# LPC408x_7x register map
File version: 0.7
CPU: CM4 r0p0, little endian, no MPU, no FPU, 3 interrupt priority bits
Registers are 32-bit, read-write, reset 0x0 unless marked. A register's access mark holds for its fields unless they carry their own. Offsets are from the block's base; [hi:lo] are bit positions; {n}, {i} and the like mark numbered series; 'fields as' and 'values as' point back to an identical list.

## UART0 — UART0/2/3
Base 0x4000C000
Same registers: UART2 0x40098000, UART3 0x4009C000
0x00 RBR ro reset not defined read-modifies — Receiver Buffer Register. Contains the next received character to be read (DLAB =0).
  [7:0] RBR — The UARTn Receiver Buffer Register contains the oldest received byte in the UARTn Rx FIFO.
0x00 THR wo reset not defined (alternate view of RBR) — Transmit Holding Regiter. The next character to be transmitted is written here (DLAB =0).
  [7:0] THR — Writing to the UARTn Transmit Holding Register causes the data to be stored in the UARTn transmit FIFO. The byte will be sent when it reaches the bottom of the FIFO and the transmitter is available.
0x00 DLL reset 0x1 (alternate view of RBR) — Divisor Latch LSB. Least significant byte of the baud rate divisor value. The full divisor is used to generate a baud rate from the fractional rate divider (DLAB =1).
  [7:0] DLLSB — The UARTn Divisor Latch LSB Register, along with the UnDLM register, determines the baud rate of the UARTn.
0x04 DLM — Divisor Latch MSB. Most significant byte of the baud rate divisor value. The full divisor is used to generate a baud rate from the fractional rate divider (DLAB =1).
  [7:0] DLMSB — The UARTn Divisor Latch MSB Register, along with the U0DLL register, determines the baud rate of the UARTn.
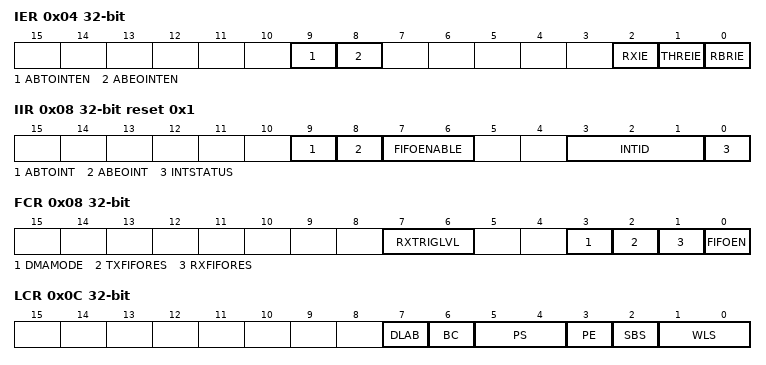
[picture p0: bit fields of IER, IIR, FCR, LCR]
0x04 IER (alternate view of DLM) — Interrupt Enable Register. Contains individual interrupt enable bits for the 7 potential UART interrupts (DLAB =0).
  [9] ABTOINTEN — Enables the auto-baud time-out interrupt.
    0=DISABLE_AUTO_BAUD_TI (Disable auto-baud time-out Interrupt.); 1=ENABLE_AUTO_BAUD_TIM (Enable auto-baud time-out Interrupt.)
  [8] ABEOINTEN — Enables the end of auto-baud interrupt.
    0=DISABLE_END_OF_AUTO_ (Disable end of auto-baud Interrupt.); 1=ENABLE_END_OF_AUTO_B (Enable end of auto-baud Interrupt.)
  [2] RXIE — RX Line Status Interrupt Enable. Enables the UARTn RX line status interrupts. The status of this interrupt can be read from UnLSR[4:1].
    0=DISABLE_THE_RX_LINE_ (Disable the RX line status interrupts.); 1=ENABLE_THE_RX_LINE_S (Enable the RX line status interrupts.)
  [1] THREIE — THRE Interrupt Enable. Enables the THRE interrupt for UARTn. The status of this can be read from UnLSR[5].
    0=DISABLE_THE_THRE_INT (Disable the THRE interrupts.); 1=ENABLE_THE_THRE_INTE (Enable the THRE interrupts.)
  [0] RBRIE — RBR Interrupt Enable. Enables the Receive Data Available interrupt for UARTn. It also controls the Character Receive Time-out interrupt.
    0=DISABLE_THE_RDA_INTE (Disable the RDA interrupts.); 1=ENABLE_THE_RDA_INTER (Enable the RDA interrupts.)
0x08 IIR ro reset 0x1 — Interrupt ID Register. Identifies which interrupt(s) are pending.
  [9] ABTOINT — Auto-baud time-out interrupt. True if auto-baud has timed out and interrupt is enabled.
  [8] ABEOINT — End of auto-baud interrupt. True if auto-baud has finished successfully and interrupt is enabled.
  [7:6] FIFOENABLE — Copies of UnFCR[0].
  [3:1] INTID — Interrupt identification. UnIER[3:1] identifies an interrupt corresponding to the UARTn Rx or TX FIFO. All other combinations of UnIER[3:1] not listed below are reserved (000,100,101,111).
    3=1_RECEIVE_LINE_S (1 - Receive Line Status (RLS).); 2=2A__RECEIVE_DATA_AV (2a - Receive Data Available (RDA).); 6=2B__CHARACTER_TIME_ (2b - Character Time-out Indicator (CTI).); 1=3_THRE_INTERRUPT
  [0] INTSTATUS — Interrupt status. Note that UnIIR[0] is active low. The pending interrupt can be determined by evaluating UnIIR[3:1].
    0=AT_LEAST_ONE_INTERRU (At least one interrupt is pending.); 1=NO_INTERRUPT_IS_PEND (No interrupt is pending.)
0x08 FCR wo (alternate view of IIR) — FIFO Control Register. Controls UART FIFO usage and modes.
  [7:6] RXTRIGLVL — RX Trigger Level. These two bits determine how many receiver UARTn FIFO characters must be written before an interrupt or DMA request is activated.
    0=TRIGGER_LEVEL_0_1_C (Trigger level 0 (1 character or 0x01).); 1=TRIGGER_LEVEL_1_4_C (Trigger level 1 (4 characters or 0x04).); 2=TRIGGER_LEVEL_2_8_C (Trigger level 2 (8 characters or 0x08).); 3=TRIGGER_LEVEL_3_14_ (Trigger level 3 (14 characters or 0x0E).)
  [3] DMAMODE — DMA Mode Select. When the FIFO enable (bit 0 of this register) is set, this bit selects the DMA mode. See Section 18.6.6.1.
  [2] TXFIFORES — TX FIFO Reset.
    0=NO_IMPACT_ON_EITHER_ (No impact on either of UARTn FIFOs.); 1=WRITING_A_LOGIC_1_TO (Writing a logic 1 to UnFCR[2] will clear all bytes in UARTn TX FIFO, reset the pointer logic. This bit is self-clearing.)
  [1] RXFIFORES — RX FIFO Reset.
    0=NO_IMPACT_ON_EITHER_ (No impact on either of UARTn FIFOs.); 1=WRITING_A_LOGIC_1_TO (Writing a logic 1 to UnFCR[1] will clear all bytes in UARTn Rx FIFO, reset the pointer logic. This bit is self-clearing.)
  [0] FIFOEN — FIFO Enable.
    0=UARTN_FIFOS_ARE_DISA (UARTn FIFOs are disabled. Must not be used in the application.); 1=ACTIVE_HIGH_ENABLE_F (Active high enable for both UARTn Rx and TX FIFOs and UnFCR[7:1] access. This bit must be set for proper UART operation. Any transition on this bit will automatically clear the related UART FIFOs.)
0x0C LCR — Line Control Register. Contains controls for frame formatting and break generation.
  [7] DLAB — Divisor Latch Access Bit
    0=DISABLE_ACCESS_TO_DI (Disable access to Divisor Latches.); 1=ENABLE_ACCESS_TO_DIV (Enable access to Divisor Latches.)
  [6] BC — Break Control
    0=DISABLE_BREAK_TRANSM (Disable break transmission.); 1=ENABLE_BREAK_TRANSMI (Enable break transmission. Output pin UARTn TXD is forced to logic 0 when UnLCR[6] is active high.)
  [5:4] PS — Parity Select
    0=ODD_PARITY_NUMBER_O (Odd parity. Number of 1s in the transmitted character and the attached parity bit will be odd.); 1=EVEN_PARITY_NUMBER_ (Even Parity. Number of 1s in the transmitted character and the attached parity bit will be even.); 2=FORCED_1_STICK_PARIT (Forced 1 stick parity.); 3=FORCED_0_STICK_PARIT (Forced 0 stick parity.)
  [3] PE — Parity Enable.
    0=DISABLE_PARITY_GENER (Disable parity generation and checking.); 1=ENABLE_PARITY_GENERA (Enable parity generation and checking.)
  [2] SBS — Stop Bit Select
    0=1_STOP_BIT_; 1=2_STOP_BITS_1_5_IF_ (2 stop bits (1.5 if UnLCR[1:0]=00).)
  [1:0] WLS — Word Length Select.
    {v}={v+5}_BIT_CHARACTER_LENG ({v+5}-bit character length) (v=0..3)
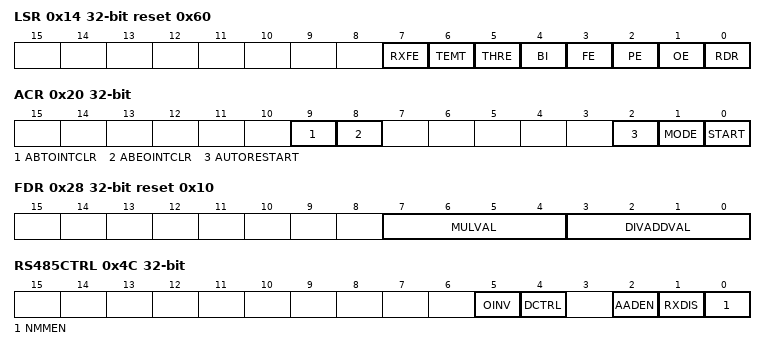
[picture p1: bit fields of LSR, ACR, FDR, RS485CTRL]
0x14 LSR ro reset 0x60 read-modifies — Line Status Register. Contains flags for transmit and receive status, including line errors.
  [7] RXFE — Error in RX FIFO . UnLSR[7] is set when a character with a Rx error such as framing error, parity error or break interrupt, is loaded into the UnRBR. This bit is cleared when the UnLSR register is read and there are no subsequent errors in the UARTn FIFO.
    0=NOERROR (UnRBR contains no UARTn RX errors or UnFCR[0]=0.); 1=ERRORS (UARTn RBR contains at least one UARTn RX error.)
  [6] TEMT — Transmitter Empty. TEMT is set when both UnTHR and UnTSR are empty; TEMT is cleared when either the UnTSR or the UnTHR contain valid data.
    0=VALIDDATA (UnTHR and/or the UnTSR contains valid data.); 1=EMPTY (UnTHR and the UnTSR are empty.)
  [5] THRE — Transmitter Holding Register Empty. THRE is set immediately upon detection of an empty UARTn THR and is cleared on a UnTHR write.
    0=VALIDDATA (UnTHR contains valid data.); 1=EMPTY (UnTHR is empty.)
  [4] BI — Break Interrupt. When RXDn is held in the spacing state (all zeroes) for one full character transmission (start, data, parity, stop), a break interrupt occurs. Once the break condition has been detected, the receiver goes idle until RXDn goes to marking state (all ones). An UnLSR read clears this status bit. The time of break detection is dependent on UnFCR[0]. Note: The break interrupt is associated with the character at the top of the UARTn RBR FIFO.
    0=INACTIVE (Break interrupt status is inactive.); 1=ACTIVE (Break interrupt status is active.)
  [3] FE — Framing Error. When the stop bit of a received character is a logic 0, a framing error occurs. An UnLSR read clears UnLSR[3]. The time of the framing error detection is dependent on UnFCR[0]. Upon detection of a framing error, the Rx will attempt to resynchronize to the data and assume that the bad stop bit is actually an early start bit. However, it cannot be assumed that the next received byte will be correct even if there is no Framing Error. Note: A framing error is associated with the character at the top of the UARTn RBR FIFO.
    0=INACTIVE (Framing error status is inactive.); 1=ACTIVE (Framing error status is active.)
  [2] PE — Parity Error. When the parity bit of a received character is in the wrong state, a parity error occurs. An UnLSR read clears UnLSR[2]. Time of parity error detection is dependent on UnFCR[0]. Note: A parity error is associated with the character at the top of the UARTn RBR FIFO.
    0=INACTIVE (Parity error status is inactive.); 1=ACTIVE (Parity error status is active.)
  [1] OE — Overrun Error. The overrun error condition is set as soon as it occurs. An UnLSR read clears UnLSR[1]. UnLSR[1] is set when UARTn RSR has a new character assembled and the UARTn RBR FIFO is full. In this case, the UARTn RBR FIFO will not be overwritten and the character in the UARTn RSR will be lost.
    0=INACTIVE (Overrun error status is inactive.); 1=ACTIVE (Overrun error status is active.)
  [0] RDR — Receiver Data Ready. UnLSR[0] is set when the UnRBR holds an unread character and is cleared when the UARTn RBR FIFO is empty.
    0=EMPTY (The UARTn receiver FIFO is empty.); 1=NOTEMPTY (The UARTn receiver FIFO is not empty.)
0x1C SCR — Scratch Pad Register. 8-bit temporary storage for software.
  [7:0] PAD — A readable, writable byte.
0x20 ACR — Auto-baud Control Register. Contains controls for the auto-baud feature.
  [9] ABTOINTCLR — Auto-baud time-out interrupt clear bit (write-only accessible). Writing a 1 will clear the corresponding interrupt in the UnIIR. Writing a 0 has no impact.
    0=NO_IMPACT_; 1=CLEAR_THE_CORRESPOND (Clear the corresponding interrupt in the IIR.)
  [8] ABEOINTCLR — End of auto-baud interrupt clear bit (write-only accessible). Writing a 1 will clear the corresponding interrupt in the UnIIR. Writing a 0 has no impact.
    values as ABTOINTCLR
  [2] AUTORESTART — Restart bit.
    0=NO_RESTART_; 1=RESTART_IN_CASE_OF_T (Restart in case of time-out (counter restarts at next UARTn Rx falling edge))
  [1] MODE — Auto-baud mode select bit.
    0=MODE_0_; 1=MODE_1_
  [0] START — Start bit. This bit is automatically cleared after auto-baud completion.
    0=AUTO_BAUD_STOP_AUTO (Auto-baud stop (auto-baud is not running).); 1=AUTO_BAUD_START_AUT (Auto-baud start (auto-baud is running). Auto-baud run bit. This bit is automatically cleared after auto-baud completion.)
0x28 FDR reset 0x10 — Fractional Divider Register. Generates a clock input for the baud rate divider.
  [7:4] MULVAL — Baud-rate pre-scaler multiplier value. This field must be greater or equal 1 for UARTn to operate properly, regardless of whether the fractional baud-rate generator is used or not.
  [3:0] DIVADDVAL — Baud-rate generation pre-scaler divisor value. If this field is 0, fractional baud-rate generator will not impact the UARTn baudrate.
0x30 TER reset 0x80 — Transmit Enable Register. Turns off UART transmitter for use with software flow control.
  [7] TXEN — When this bit is 1, as it is after a Reset, data written to the THR is output on the TXD pin as soon as any preceding data has been sent. If this bit is cleared to 0 while a character is being sent, the transmission of that character is completed, but no further characters are sent until this bit is set again. In other words, a 0 in this bit blocks the transfer of characters from the THR or TX FIFO into the transmit shift register. Software implementing software-handshaking can clear this bit when it receives an XOFF character (DC3). Software can set this bit again when it receives an XON (DC1) character.
0x4C RS485CTRL — RS-485/EIA-485 Control. Contains controls to configure various aspects of RS-485/EIA-485 modes.
  [5] OINV — Direction control pin polarity. This bit reverses the polarity of the direction control signal on the Un_OE pin.
    0=DIRLOW (The direction control pin will be driven to logic 0 when the transmitter has data to be sent. It will be driven to logic 1 after the last bit of data has been transmitted.); 1=DIRHIGH (The direction control pin will be driven to logic 1 when the transmitter has data to be sent. It will be driven to logic 0 after the last bit of data has been transmitted.)
  [4] DCTRL — Direction control enable.
    0=DISABLE_AUTO_DIRECTI (Disable Auto Direction Control.); 1=ENABLE_AUTO_DIRECTIO (Enable Auto Direction Control.)
  [2] AADEN — AAD enable.
    0=DISABLED (Auto Address Detect (AAD) is disabled.); 1=ENABLED (Auto Address Detect (AAD) is enabled.)
  [1] RXDIS — Receiver enable.
    0=ENABLED (The receiver is enabled.); 1=DISABLED (The receiver is disabled.)
  [0] NMMEN — NMM enable.
    0=DISABLED (RS-485/EIA-485 Normal Multidrop Mode (NMM) is disabled.); 1=ENABLED (RS-485/EIA-485 Normal Multidrop Mode (NMM) is enabled. In this mode, an address is detected when a received byte has the parity bit = 1, generating a received data interrupt. See Section 18.6.16 RS-485/EIA-485 modes of operation.)
0x50 RS485ADRMATCH — RS-485/EIA-485 address match. Contains the address match value for RS-485/EIA-485 mode.
  [7:0] ADRMATCH — Contains the address match value.
0x54 RS485DLY — RS-485/EIA-485 direction control delay.
  [7:0] DLY — Contains the direction control (UnOE) delay value. This register works in conjunction with an 8-bit counter.
